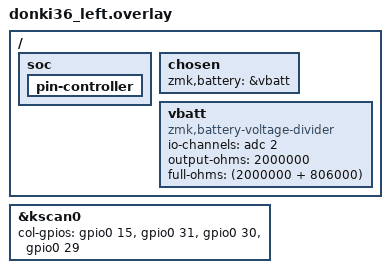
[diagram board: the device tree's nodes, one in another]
/*
 * Copyright (c) 2020 Pete Johanson
 *
 * SPDX-License-Identifier: MIT
 */

#include "donki36.dtsi"

/ {
    soc {
        pin-controller {
            #binding-cells = <0>;
        };
    };
};

&kscan0 {
	col-gpios
        = <&gpio0 15 GPIO_ACTIVE_HIGH>
        , <&gpio0 31 GPIO_ACTIVE_HIGH>
        , <&gpio0 30 GPIO_ACTIVE_HIGH>
        , <&gpio0 29 GPIO_ACTIVE_HIGH>
		;
};

/{
	chosen {
		zmk,battery = &vbatt;
	};
	vbatt: vbatt {
		compatible = "zmk,battery-voltage-divider";
		io-channels = <&adc 2>;
		output-ohms = <2000000>;
		full-ohms = <(2000000 + 806000)>;
	};
};

#include "donki36__esb_addr.dtsi"


/ {
    soc {
        pin-controller {
            #binding-cells = <0>;
        };
    };
};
